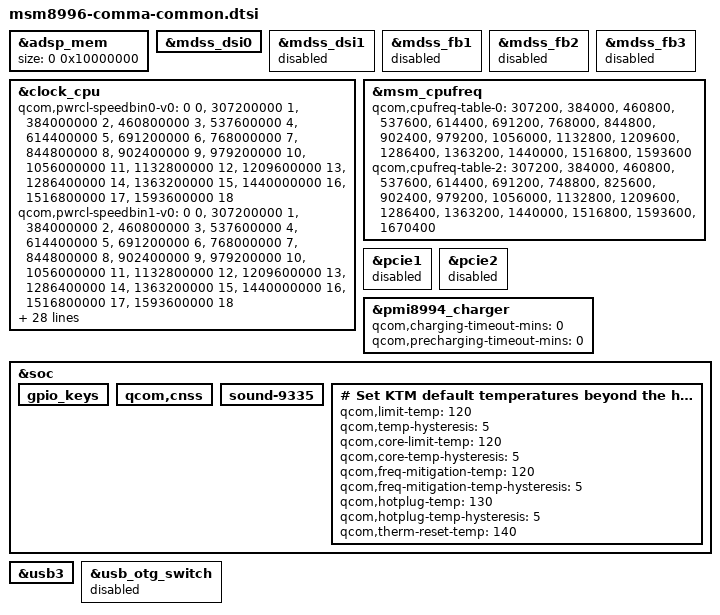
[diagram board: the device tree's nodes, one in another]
/*
 * Copyright (C) 2018, Comma.ai, Inc.
 *
 * This program is free software; you can redistribute it and/or modify
 * it under the terms of the GNU General Public License version 2 and
 * only version 2 as published by the Free Software Foundation.
 *
 * This program is distributed in the hope that it will be useful,
 * but WITHOUT ANY WARRANTY; without even the implied warranty of
 * MERCHANTABILITY or FITNESS FOR A PARTICULAR PURPOSE.  See the
 * GNU General Public License for more details.
 */

&adsp_mem {
	size = <0 0x10000000>;
};

&mdss_dsi0 {
	/delete-property/ qcom,platform-bklight-en-gpio;
};

&mdss_dsi1 {
	status = "disabled";
};

&mdss_fb1 {
	status = "disabled";
};

&mdss_fb2 {
	status = "disabled";
};

&mdss_fb3 {
	status = "disabled";
};

&clock_cpu {
        qcom,pwrcl-speedbin0-v0 =
                <          0  0 >,
                <  307200000  1 >,
                <  384000000  2 >,
                <  460800000  3 >,
                <  537600000  4 >,
                <  614400000  5 >,
                <  691200000  6 >,
                <  768000000  7 >,
                <  844800000  8 >,
                <  902400000  9 >,
                <  979200000 10 >,
                < 1056000000 11 >,
                < 1132800000 12 >,
                < 1209600000 13 >,
                < 1286400000 14 >,
                < 1363200000 15 >,
                < 1440000000 16 >,
                < 1516800000 17 >,
                < 1593600000 18 >;
        qcom,pwrcl-speedbin1-v0 =
                <          0  0 >,
                <  307200000  1 >,
                <  384000000  2 >,
                <  460800000  3 >,
                <  537600000  4 >,
                <  614400000  5 >,
                <  691200000  6 >,
                <  768000000  7 >,
                <  844800000  8 >,
                <  902400000  9 >,
                <  979200000 10 >,
                < 1056000000 11 >,
                < 1132800000 12 >,
                < 1209600000 13 >,
                < 1286400000 14 >,
                < 1363200000 15 >,
                < 1440000000 16 >,
                < 1516800000 17 >,
                < 1593600000 18 >;
        qcom,pwrcl-speedbin2-v0 =
                <          0  0 >,
                <  307200000  1 >,
                <  384000000  2 >,
                <  460800000  3 >,
                <  537600000  4 >,
                <  614400000  5 >,
                <  691200000  6 >,
                <  768000000  7 >,
                <  844800000  8 >,
                <  902400000  9 >,
                <  979200000 10 >,
                < 1056000000 11 >,
                < 1132800000 12 >,
                < 1209600000 13 >,
                < 1286400000 14 >,
                < 1363200000 15 >,
                < 1440000000 16 >,
                < 1516800000 17 >,
                < 1593600000 18 >;
        qcom,perfcl-speedbin0-v0 =
                <          0  0 >,
                <  307200000  1 >,
                <  384000000  2 >,
                <  460800000  3 >,
                <  537600000  4 >,
                <  614400000  5 >,
                <  691200000  6 >,
                <  748800000  7 >,
                <  825600000  8 >,
                <  902400000  9 >,
                <  979200000 10 >,
                < 1056000000 11 >,
                < 1132800000 12 >,
                < 1209600000 13 >,
                < 1286400000 14 >,
                < 1363200000 15 >,
                < 1440000000 16 >,
                < 1516800000 17 >,
                < 1593600000 18 >,
                < 1670400000 19 >;
        qcom,perfcl-speedbin1-v0 =
                <          0  0 >,
                <  307200000  1 >,
                <  384000000  2 >,
                <  460800000  3 >,
                <  537600000  4 >,
                <  614400000  5 >,
                <  691200000  6 >,
                <  748800000  7 >,
                <  825600000  8 >,
                <  902400000  9 >,
                <  979200000 10 >,
                < 1056000000 11 >,
                < 1132800000 12 >,
                < 1209600000 13 >,
                < 1286400000 14 >,
                < 1363200000 15 >,
                < 1440000000 16 >,
                < 1516800000 17 >,
                < 1593600000 18 >,
                < 1670400000 19 >;
        qcom,perfcl-speedbin2-v0 =
                <          0  0 >,
                <  307200000  1 >,
                <  384000000  2 >,
                <  460800000  3 >,
                <  537600000  4 >,
                <  614400000  5 >,
                <  691200000  6 >,
                <  748800000  7 >,
                <  825600000  8 >,
                <  902400000  9 >,
                <  979200000 10 >,
                < 1056000000 11 >,
                < 1132800000 12 >,
                < 1209600000 13 >,
                < 1286400000 14 >,
                < 1363200000 15 >,
                < 1440000000 16 >,
                < 1516800000 17 >,
                < 1593600000 18 >,
                < 1670400000 19 >;
};


&msm_cpufreq {
        qcom,cpufreq-table-0 =
                <  307200 >,
                <  384000 >,
                <  460800 >,
                <  537600 >,
                <  614400 >,
                <  691200 >,
                <  768000 >,
                <  844800 >,
                <  902400 >,
                <  979200 >,
                < 1056000 >,
                < 1132800 >,
                < 1209600 >,
                < 1286400 >,
                < 1363200 >,
                < 1440000 >,
                < 1516800 >,
                < 1593600 >;
        qcom,cpufreq-table-2 =
                <  307200 >,
                <  384000 >,
                <  460800 >,
                <  537600 >,
                <  614400 >,
                <  691200 >,
                <  748800 >,
                <  825600 >,
                <  902400 >,
                <  979200 >,
                < 1056000 >,
                < 1132800 >,
                < 1209600 >,
                < 1286400 >,
                < 1363200 >,
                < 1440000 >,
                < 1516800 >,
                < 1593600 >,
                < 1670400 >;
};

&pcie1 {
	status = "disabled";
};

&pcie2 {
	status = "disabled";
};

&pmi8994_charger {
	qcom,charging-timeout-mins = <0>;
	qcom,precharging-timeout-mins = <0>;
};

&soc {
	/delete-node/ gen-vkeys;

	gpio_keys {
		/delete-node/ cam_focus;
		/delete-node/ cam_snapshot;
	};

	qcom,cnss {
		/delete-property/ qcom,wlan-ramdump-dynamic;
	};

	sound-9335 {
		/delete-property/ qcom,hph-en0-gpio;
		/delete-property/ qcom,hph-en1-gpio;
		/delete-property/ qcom,us-euro-gpios;
		/delete-property/ qcom,wsa-aux-dev-prefix;
		/delete-property/ qcom,wsa-devs;
		/delete-property/ qcom,wsa-max-devs;
	};

        # Set KTM default temperatures beyond the hardware watchdog limit
        # of ~115C. We want msm-thermal available for later use, but we
        # don't want it to do anything unless and until instructed by the
        # qcom thermal-engine or its clients.
        qcom,msm-thermal {
                qcom,limit-temp = <120>;
                qcom,temp-hysteresis = <5>;
                qcom,core-limit-temp = <120>;
                qcom,core-temp-hysteresis = <5>;
                qcom,freq-mitigation-temp = <120>;
                qcom,freq-mitigation-temp-hysteresis = <5>;
                qcom,hotplug-temp = <130>;
                qcom,hotplug-temp-hysteresis = <5>;
                qcom,therm-reset-temp = <140>;
        };
};

&usb3 {
	/delete-property/ vbus_dwc3-supply;
};

&usb_otg_switch {
	status = "disabled";
};
